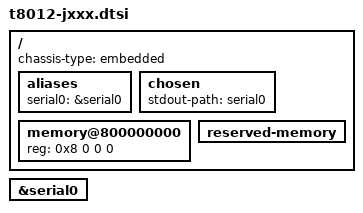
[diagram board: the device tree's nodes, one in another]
// SPDX-License-Identifier: GPL-2.0+ OR MIT
/*
 * Common Device Tree for all T2 devices
 *
 * target-type: J132, J137, J140a, J140k, J152f, J160, J174, J185, J185f
 * J213, J214k, J215, J223, J230k, J680, J780
 *
 * Copyright (c) 2024, Nick Chan <towinchenmi@gmail.com>
 */

#include "t8012.dtsi"

/ {
	chassis-type = "embedded";

	aliases {
		serial0 = &serial0;
	};

	chosen {
		#address-cells = <2>;
		#size-cells = <2>;
		ranges;

		stdout-path = "serial0";
	};

	memory@800000000 {
		device_type = "memory";
		reg = <0x8 0 0 0>; /* To be filled by loader */
	};

	reserved-memory {
		#address-cells = <2>;
		#size-cells = <2>;
		ranges;

		/* To be filled by loader */
	};
};

&serial0 {
	status = "okay";
};
